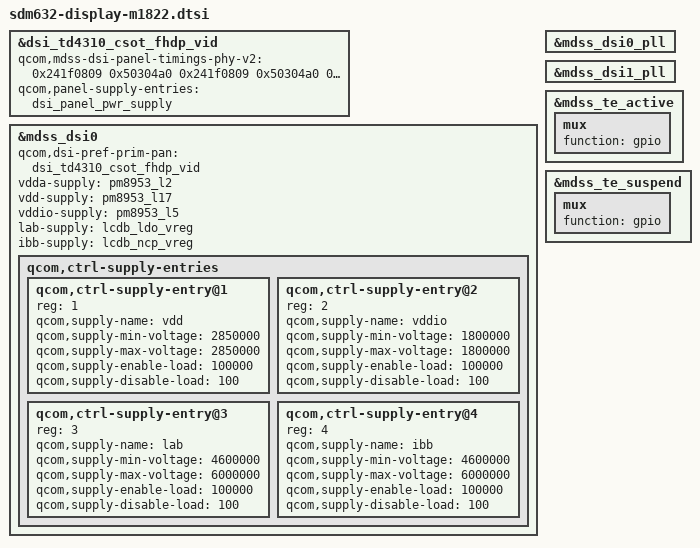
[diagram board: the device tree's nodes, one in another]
/*
 * Copyright (c) 2017, The Linux Foundation. All rights reserved.
 *
 * This program is free software; you can redistribute it and/or modify
 * it under the terms of the GNU General Public License version 2 and
 * only version 2 as published by the Free Software Foundation.
 *
 * This program is distributed in the hope that it will be useful,
 * but WITHOUT ANY WARRANTY; without even the implied warranty of
 * MERCHANTABILITY or FITNESS FOR A PARTICULAR PURPOSE.  See the
 * GNU General Public License for more details.
 */

#include "dsi-panel-td4310-csot-fhdp-video.dtsi"

&dsi_td4310_csot_fhdp_vid {
	qcom,mdss-dsi-panel-timings-phy-v2 = <0x241f0809 0x50304a0 0x241f0809 0x50304a0 0x241f0809 0x50304a0 0x241f0809 0x50304a0 0x241b0809 0x50304a0>;
    qcom,panel-supply-entries = <&dsi_panel_pwr_supply>;
};

&mdss_dsi0 {
	qcom,dsi-pref-prim-pan = <&dsi_td4310_csot_fhdp_vid>;
	vdda-supply = <&pm8953_l2>;
	vdd-supply = <&pm8953_l17>;
	vddio-supply = <&pm8953_l5>;
	lab-supply = <&lcdb_ldo_vreg>;
	ibb-supply = <&lcdb_ncp_vreg>;

	qcom,ctrl-supply-entries {
		#address-cells = <1>;
		#size-cells = <0>;

		qcom,ctrl-supply-entry@1 {
			reg = <1>;
			qcom,supply-name = "vdd";
			qcom,supply-min-voltage = <2850000>;
			qcom,supply-max-voltage = <2850000>;
			qcom,supply-enable-load = <100000>;
			qcom,supply-disable-load = <100>;
		};
		qcom,ctrl-supply-entry@2 {
			reg = <2>;
			qcom,supply-name = "vddio";
			qcom,supply-min-voltage = <1800000>;
			qcom,supply-max-voltage = <1800000>;
			qcom,supply-enable-load = <100000>;
			qcom,supply-disable-load = <100>;
		};
		qcom,ctrl-supply-entry@3 {
			reg = <3>;
			qcom,supply-name = "lab";
			qcom,supply-min-voltage = <4600000>;
			qcom,supply-max-voltage = <6000000>;
			qcom,supply-enable-load = <100000>;
			qcom,supply-disable-load = <100>;
		};
		qcom,ctrl-supply-entry@4 {
			reg = <4>;
			qcom,supply-name = "ibb";
			qcom,supply-min-voltage = <4600000>;
			qcom,supply-max-voltage = <6000000>;
			qcom,supply-enable-load = <100000>;
			qcom,supply-disable-load = <100>;
		};
	};
};

&mdss_dsi0_pll {
	/delete-property/ qcom,dsi-pll-ssc-en;
	/delete-property/ qcom,dsi-pll-ssc-mode;
};

&mdss_dsi1_pll {
	/delete-property/ qcom,dsi-pll-ssc-en;
	/delete-property/ qcom,dsi-pll-ssc-mode;
};

&mdss_te_active {
	mux {
		function = "gpio";
	};
};

&mdss_te_suspend {
	mux {
		function = "gpio";
	};
};
